# max78002 register map
Vendor: Maxim-Integrated; Series: ARMCM4; File version: 1.0
CPU: CM4 r2p1, little endian, MPU, FPU, 3 interrupt priority bits
Registers are 32-bit, read-write, reset 0x0 unless marked. A register's access mark holds for its fields unless they carry their own. Offsets are from the block's base; [hi:lo] are bit positions; {n}, {i} and the like mark numbered series; 'fields as' and 'values as' point back to an identical list.

## AES — AES Keys.
Base 0x40007400
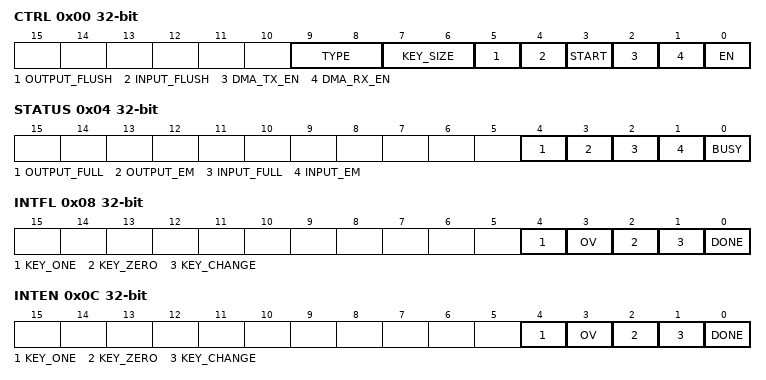
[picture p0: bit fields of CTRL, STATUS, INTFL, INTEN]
0x00 CTRL — AES Control Register
  [9:8] TYPE — Encryption Type Selection
  [7:6] KEY_SIZE — Encryption Key Size
    0=AES128 (128 Bits.); 1=AES192 (192 Bits.); 2=AES256 (256 Bits.)
  [5] OUTPUT_FLUSH — Flush the data output FIFO
  [4] INPUT_FLUSH — Flush the data input FIFO
  [3] START — Start AES Calculation
  [2] DMA_TX_EN — DMA Request To Write Data Input FIFO
  [1] DMA_RX_EN — DMA Request To Read Data Output FIFO
  [0] EN — AES Enable
0x04 STATUS — AES Status Register
  [4] OUTPUT_FULL — Data output FIFO full status
  [3] OUTPUT_EM — Data output FIFO empty status
  [2] INPUT_FULL — Data input FIFO full status
  [1] INPUT_EM — Data input FIFO empty status
  [0] BUSY — AES Busy Status
0x08 INTFL — AES Interrupt Flag Register
  [4] KEY_ONE
  [3] OV — Data Output FIFO Overrun Interrupt
  [2] KEY_ZERO — External AES Key Zero Interrupt
  [1] KEY_CHANGE — External AES Key Changed Interrupt
  [0] DONE — AES Done Interrupt
0x0C INTEN — AES Interrupt Enable Register
  [4] KEY_ONE
  [3] OV — Data Output FIFO Overrun Interrupt Enable
  [2] KEY_ZERO — External AES Key Zero Interrupt Enable
  [1] KEY_CHANGE — External AES Key Changed Interrupt Enable
  [0] DONE — AES Done Interrupt Enable
0x10 FIFO — AES Data Register
  [0] DATA — AES FIFO

## AESKEYS — AES Key Registers.
Base 0x40007800
{0x0+0x80*i} KEY{i} (i=0..3) — AES Key {i}.

## CAMERAIF — Parallel Camera Interface.
Base 0x4000E000
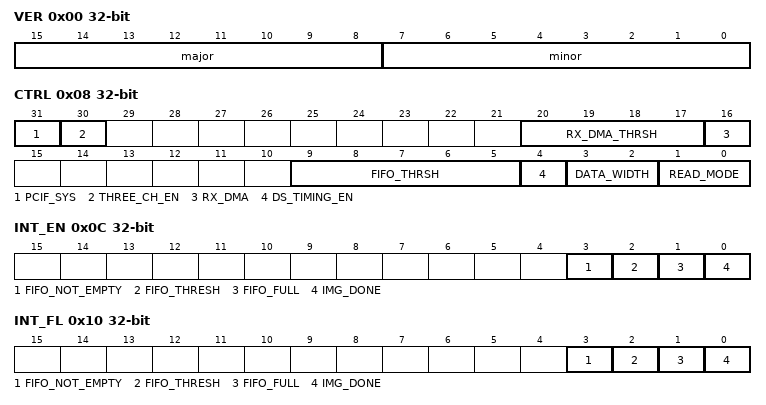
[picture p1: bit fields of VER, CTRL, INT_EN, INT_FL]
0x00 VER — Hardware Version.
  [15:8] major — Major Version Number.
  [7:0] minor — Minor Version Number.
0x04 FIFO_SIZE — FIFO Depth.
  [7:0] fifo_size
0x08 CTRL — Control Register.
  [31] PCIF_SYS — PCIF Control.
    0=dis (PCIF disabled.); 1=en (PCIF enabled.)
  [30] THREE_CH_EN — Three-channel mode enable.
  [20:17] RX_DMA_THRSH — DMA Threshold.
  [16] RX_DMA — DMA Enable.
    0=dis (DMA disabled.); 1=en (DMA enabled.)
  [9:5] FIFO_THRSH — Data FIFO Threshold.
  [4] DS_TIMING_EN — DS Timing Enable.
    0=dis (Timing from VSYNC and HSYNC.); 1=en (Timing embedded in data using SAV and EAV codes.)
  [3:2] DATA_WIDTH
    0=8bit; 1=10bit; 2=12bit
  [1:0] READ_MODE
    0=dis (Camera Interface Disabled.); 1=single_img (Single Image Capture.); 2=Continuous Image Capture
0x0C INT_EN — Interupt Enable Register.
  [3] FIFO_NOT_EMPTY
  [2] FIFO_THRESH — FIFO Threshold Level Met.
  [1] FIFO_FULL
  [0] IMG_DONE — Image Done.
0x10 INT_FL — Interupt Flag Register.
  fields as INT_EN
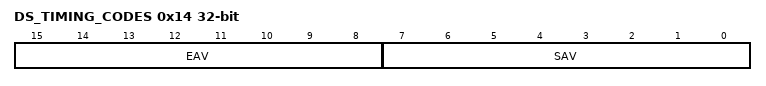
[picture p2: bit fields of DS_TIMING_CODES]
0x14 DS_TIMING_CODES — DS Timing Code Register.
  [15:8] EAV — End Active Video Code.
  [7:0] SAV — Start Active Video Code.
0x30 FIFO_DATA
  [31:0] DATA — Data from FIFO to be read by DMA.

## CRC — CRC Registers.
Base 0x4000F000
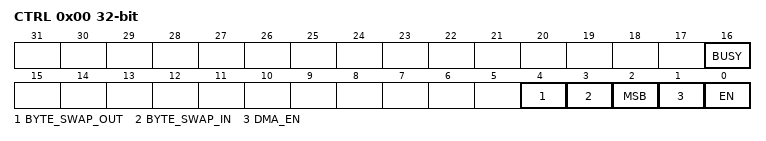
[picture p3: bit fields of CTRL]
0x00 CTRL — CRC Control
  [16] BUSY — CRC Busy
  [4] BYTE_SWAP_OUT — Byte Swap CRC Value Output
  [3] BYTE_SWAP_IN — Byte Swap CRC Data Input
  [2] MSB — MSB Select
  [1] DMA_EN — DMA Request Enable
  [0] EN — CRC Enable
0x04 DATAIN32 — CRC Data Input
  [31:0] DATA — CRC Data
{0x4+2i} DATAIN16[{i}] (i=0..1) 16-bit — CRC Data Input
  [15:0] DATA — CRC Data
{0x4+i} DATAIN8[{i}] (i=0..3) 8-bit — CRC Data Input
  [7:0] DATA — CRC Data
0x08 POLY — CRC Polynomial
0x0C VAL — Current CRC Value
  [31:0] VALUE

## FCR — Function Control Register.
Base 0x40000800
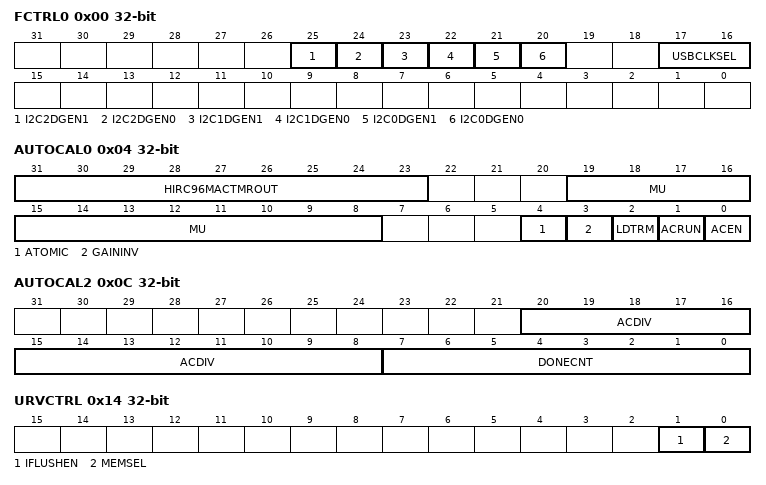
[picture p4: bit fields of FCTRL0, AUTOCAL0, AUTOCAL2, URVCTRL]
0x00 FCTRL0 — Function Control 0.
  [25] I2C2DGEN1 — I2C2 SCL Pad Deglitcher enable.
    0=dis (Deglitcher disabled.); 1=en (Deglitcher enabled.)
  [24] I2C2DGEN0 — I2C2 SDA Pad Deglitcher enable.
    0=dis (Deglitcher disabled.); 1=en (Deglitcher enabled.)
  [23] I2C1DGEN1 — I2C1 SCL Pad Deglitcher enable.
    0=dis (Deglitcher disabled.); 1=en (Deglitcher enabled.)
  [22] I2C1DGEN0 — I2C1 SDA Pad Deglitcher enable.
    0=dis (Deglitcher disabled.); 1=en (Deglitcher enabled.)
  [21] I2C0DGEN1 — I2C0 SCL Pad Deglitcher enable.
    0=dis (Deglitcher disabled.); 1=en (Deglitcher enabled.)
  [20] I2C0DGEN0 — I2C0 SDA Pad Deglitcher enable.
    0=dis (Deglitcher disabled.); 1=en (Deglitcher enabled.)
  [17:16] USBCLKSEL — USB Core Clock Select.
0x04 AUTOCAL0 — Automatic Calibration 0.
  [31:23] HIRC96MACTMROUT — HIRC96M Trim Value.
  [19:8] MU — MU value.
  [4] ATOMIC — Atomic mode.
    0=not (Not Running.); 1=run (Running.)
  [3] GAININV — Invert Gain.
    0=not (Not Running.); 1=run (Running.)
  [2] LDTRM — Load Trim.
  [1] ACRUN — Autocalibration Run.
    0=not (Not Running.); 1=run (Running.)
  [0] ACEN — Auto-calibration Enable.
    0=dis (Disabled.); 1=en (Enabled.)
0x08 AUTOCAL1 — Automatic Calibration 1.
  [8:0] INITTRM — Initial Trim Setting.
0x0C AUTOCAL2 — Automatic Calibration 2
  [20:8] ACDIV — Auto-callibration Div Setting.
  [7:0] DONECNT — Auto-callibration Done Counter Setting.
0x10 URVBOOTADDR — RISC-V Boot Address.
0x14 URVCTRL — RISC-V Control Register.
  [1] IFLUSHEN — URV instruction flush enable.
  [0] MEMSEL — RAM2, RAM3 exclusive ownership.
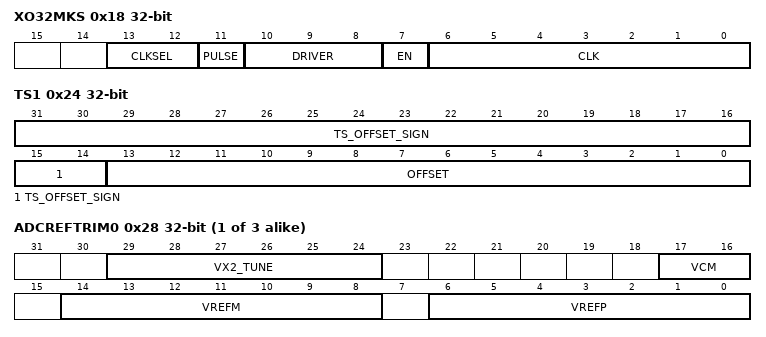
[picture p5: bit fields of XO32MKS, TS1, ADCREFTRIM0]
0x18 XO32MKS — RISC-V Control Register.
  [13:12] CLKSEL — Kick Start XO Clock Select
    0=none (No kick start clock.); 1=Test Clock in P1.2 (TMR3[22]=1); 2=ISO (Internal secondary oscilator); 3=IPO (Internal Primary Oscilator)
  [11] PULSE — Kick Start XO 2X Pulse
  [10:8] DRIVER — Kick Start XO Driver
  [7] EN — Kick Start XO Enable
  [6:0] CLK — Kick Start XO Counter Setting
0x20 TS0 — Temp Sensor trim0
  [11:0] GAIN — Unsigned gain for temp sensor normalization Temp degrees C = (ADC result * TS_GAIN) + TS_OFFSET.
0x24 TS1 — Temp Sensor trim1
  [31:14] TS_OFFSET_SIGN — Sign extension of TS_OFFSET[13:0]
  [13:0] OFFSET — Signed gain for temp sensor normalization Temp degrees C = (ADC result * TS_GAIN) + TS_OFFSET.
{0x28+4i} ADCREFTRIM{i} (i=0..2) — Temp Sensor trim1
  [29:24] VX2_TUNE — Controls tuning capacitor in fine DAC (offset binary)
  [17:16] VCM — Trimming code for VCM output of reference buffer
  [14:8] VREFM — Trimming code for VREFM output of reference buffer
  [6:0] VREFP — Trimming code for VREFP output of reference buffer
